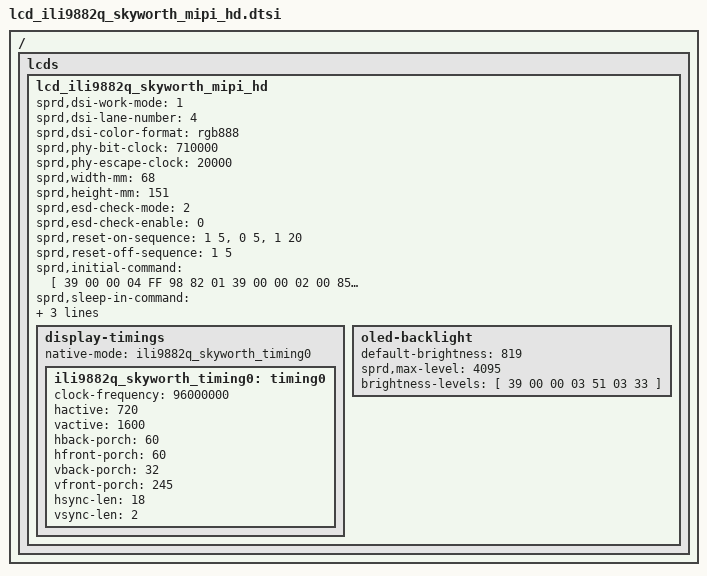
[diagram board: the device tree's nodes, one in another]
/ {
	fragment {
		target-path = "/";
		__overlay__ {
			lcds {
				lcd_ili9882q_skyworth_mipi_hd: lcd_ili9882q_skyworth_mipi_hd {
				       sprd,dsi-work-mode = <1>; /* video burst mode*/
				       sprd,dsi-lane-number = <4>;
				       sprd,dsi-color-format = "rgb888";

				       sprd,phy-bit-clock = <710000>;  /* kbps */
				       sprd,phy-escape-clock = <20000>;/* kHz */

				       sprd,width-mm = <68>;
				       sprd,height-mm = <151>;

				       sprd,esd-check-mode = <2>;
				       sprd,esd-check-enable = <0>;

				       sprd,reset-on-sequence = <1 5>, <0 5>, <1 20>;
				       sprd,reset-off-sequence = <1 5>;

				       sprd,initial-command = [
					       	       39 00 00 04 FF 98 82 01
						       39 00 00 02 00 85
						       39 00 00 02 01 32
						       39 00 00 02 02 00
						       39 00 00 02 03 00
						       39 00 00 02 04 CC
						       39 00 00 02 05 35
						       39 00 00 02 06 00
						       39 00 00 02 07 00
						       39 00 00 02 08 85
						       39 00 00 02 09 02
						       39 00 00 02 0A 72
						       39 00 00 02 0B 00
						       39 00 00 02 28 86
						       39 00 00 02 29 4E
						       39 00 00 02 EE 17
						       39 00 00 02 2A 85
						       39 00 00 02 2B 4D
						       39 00 00 02 F0 00
						       39 00 00 02 EF 45
						       39 00 00 02 31 2A
						       39 00 00 02 32 07
						       39 00 00 02 33 07
						       39 00 00 02 34 07
						       39 00 00 02 35 00
						       39 00 00 02 36 07
						       39 00 00 02 37 01
						       39 00 00 02 38 22
						       39 00 00 02 39 23
						       39 00 00 02 3A 07
						       39 00 00 02 3B 10
						       39 00 00 02 3C 12
						       39 00 00 02 3D 14
						       39 00 00 02 3E 16
						       39 00 00 02 3F 07
						       39 00 00 02 40 0C
						       39 00 00 02 41 0E
						       39 00 00 02 42 07
						       39 00 00 02 43 2A
						       39 00 00 02 44 2A
						       39 00 00 02 45 2A
						       39 00 00 02 46 07
						       39 00 00 02 47 2A
						       39 00 00 02 48 07
						       39 00 00 02 49 07
						       39 00 00 02 4A 07
						       39 00 00 02 4B 00
						       39 00 00 02 4C 07
						       39 00 00 02 4D 01
						       39 00 00 02 4E 22
						       39 00 00 02 4F 23
						       39 00 00 02 50 07
						       39 00 00 02 51 11
						       39 00 00 02 52 13
						       39 00 00 02 53 15
						       39 00 00 02 54 17
						       39 00 00 02 55 07
						       39 00 00 02 56 0D
						       39 00 00 02 57 0F
						       39 00 00 02 58 07
						       39 00 00 02 59 2A
						       39 00 00 02 5A 2A
						       39 00 00 02 5B 2A
						       39 00 00 02 5C 07
						       39 00 00 02 61 2A
						       39 00 00 02 62 07
						       39 00 00 02 63 07
						       39 00 00 02 64 07
						       39 00 00 02 65 00
						       39 00 00 02 66 07
						       39 00 00 02 67 01
						       39 00 00 02 68 22
						       39 00 00 02 69 23
						       39 00 00 02 6A 07
						       39 00 00 02 6B 17
						       39 00 00 02 6C 15
						       39 00 00 02 6D 13
						       39 00 00 02 6E 11
						       39 00 00 02 6F 07
						       39 00 00 02 70 0F
						       39 00 00 02 71 0D
						       39 00 00 02 72 07
						       39 00 00 02 73 2A
						       39 00 00 02 74 2A
						       39 00 00 02 75 2A
						       39 00 00 02 76 07
						       39 00 00 02 77 2A
						       39 00 00 02 78 07
						       39 00 00 02 79 07
						       39 00 00 02 7A 07
						       39 00 00 02 7B 00
						       39 00 00 02 7C 07
						       39 00 00 02 7D 01
						       39 00 00 02 7E 22
						       39 00 00 02 7F 23
						       39 00 00 02 80 07
						       39 00 00 02 81 16
						       39 00 00 02 82 14
						       39 00 00 02 83 12
						       39 00 00 02 84 10
						       39 00 00 02 85 07
						       39 00 00 02 86 0E
						       39 00 00 02 87 0C
						       39 00 00 02 88 07
						       39 00 00 02 89 2A
						       39 00 00 02 8A 2A
						       39 00 00 02 8B 2A
						       39 00 00 02 8C 07
						       39 00 00 02 A0 01
						       39 00 00 02 A1 00
						       39 00 00 02 A2 00
						       39 00 00 02 A3 00
						       39 00 00 02 A4 00
						       39 00 00 02 A7 00
						       39 00 00 02 A8 00
						       39 00 00 02 A9 00
						       39 00 00 02 AA 00
						       39 00 00 02 B0 34
						       39 00 00 02 B2 04
						       39 00 00 02 B9 10
						       39 00 00 02 BA 02
						       39 00 00 02 C1 10
						       39 00 00 02 D0 01
						       39 00 00 02 D1 11
						       39 00 00 02 D2 40
						       39 00 00 02 D5 56
						       39 00 00 02 D6 91
						       39 00 00 02 D8 05
						       39 00 00 02 D9 11
						       39 00 00 02 DA 54
						       39 00 00 02 Dc 40
						       39 00 00 02 E2 45
						       39 00 00 02 E6 33
						       39 00 00 02 EA 0F
						       39 00 00 02 E7 54
						       39 00 00 02 E0 7E
						       39 00 00 04 FF 98 82 02
						       39 00 00 02 F1 1C
						       39 00 00 02 4B 5A
						       39 00 00 02 50 CA
						       39 00 00 02 51 00
						       39 00 00 02 06 8C
						       39 00 00 02 0B A0
						       39 00 00 02 0C 00
						       39 00 00 02 0D 22
						       39 00 00 02 0E FA
						       39 00 00 02 4E 11
						       39 00 00 02 4D CE
						       39 00 00 02 F2 4A
						       39 00 00 02 40 4A
						       39 00 00 04 FF 98 82 05
						       39 00 00 02 03 01
						       39 00 00 02 04 1A
						       39 00 00 02 58 61
						       39 00 00 02 63 79
						       39 00 00 02 64 79
						       39 00 00 02 68 B5
						       39 00 00 02 69 BB
						       39 00 00 02 6A 8D
						       39 00 00 02 6B 7F
						       39 00 00 02 85 77
						       39 00 00 02 47 0A
						       39 00 00 02 C8 F1
						       39 00 00 02 C9 F1
						       39 00 00 02 CA B5
						       39 00 00 02 CB B5
						       39 00 00 02 D0 F7
						       39 00 00 02 D1 F7
						       39 00 00 02 D2 BB
						       39 00 00 02 D3 BB
						       39 00 00 04 FF 98 82 06
						       39 00 00 02 D9 1F
						       39 00 00 02 C0 40
						       39 00 00 02 C1 16
						       39 00 00 02 80 08
						       39 00 00 04 FF 98 82 07
						       39 00 00 02 C0 01
						       39 00 00 02 CB C0
						       39 00 00 02 CC BB
						       39 00 00 02 CD 83
						       39 00 00 02 CE 83
						       39 00 00 04 FF 98 82 08
						       39 00 00 1C E0 00 24 4C 6D 9D 50 C8 EC 19 3F 95 7C AF DF 0E AA 41 7E A4 D3 FE FA 2C 68 9A 03 EC
						       39 00 00 1C E1 00 24 4C 6D 9D 50 C8 EC 19 3F 95 7C AF DF 0E AA 41 7E A4 D3 FE FA 2C 68 9A 03 EC
						       39 00 00 04 FF 98 82 0B
						       39 00 00 02 9A 44
						       39 00 00 02 9B 6C
						       39 00 00 02 9C 03
						       39 00 00 02 9D 03
						       39 00 00 02 9E 6E
						       39 00 00 02 9F 6E
						       39 00 00 02 AB E0
						       39 00 00 02 AC 7F
						       39 00 00 02 AD 3F
						       39 00 00 04 FF 98 82 0E
						       39 00 00 02 11 10
						       39 00 00 02 13 05
						       39 00 00 02 00 A0
						       39 00 00 04 FF 98 82 06
						       39 00 00 02 06 A4
						       39 00 00 04 FF 98 82 03
						       39 00 00 02 83 20
						       39 00 00 02 84 00
						       39 00 00 04 FF 98 82 00
						       39 00 00 03 68 04 01
						       39 00 00 03 51 00 00
						       39 00 00 02 53 2C
						       39 00 00 02 35 00
						       39 78 00 02 11 00
						       39 14 00 02 29 00
						       39 00 00 04 FF 98 82 0F
						       ];

				        sprd,sleep-in-command = [
						39 00 00 04 FF 98 82 00
						13 0A 00 02 28 00
						13 78 00 02 10 00
						39 00 00 04 FF 98 82 0F
						];
					sprd,sleep-out-command = [
						13 78 00 02 11 00
						13 14 00 02 29 00
						];

					display-timings {
						native-mode = <&ili9882q_skyworth_timing0>;

						ili9882q_skyworth_timing0: timing0 {
						clock-frequency = <96000000>;
						hactive = <720>;
						vactive = <1600>;
						hback-porch = <60>;
						hfront-porch = <60>;
						vback-porch = <32>;
						vfront-porch = <245>;
						hsync-len = <18>;
						vsync-len = <2>;
						};
					};

					oled-backlight {
						default-brightness = <819>;
						sprd,max-level = <4095>;
						brightness-levels = [
							39 00 00 03 51 03 33
						];
					};
				};
			};
		};
	};
};
